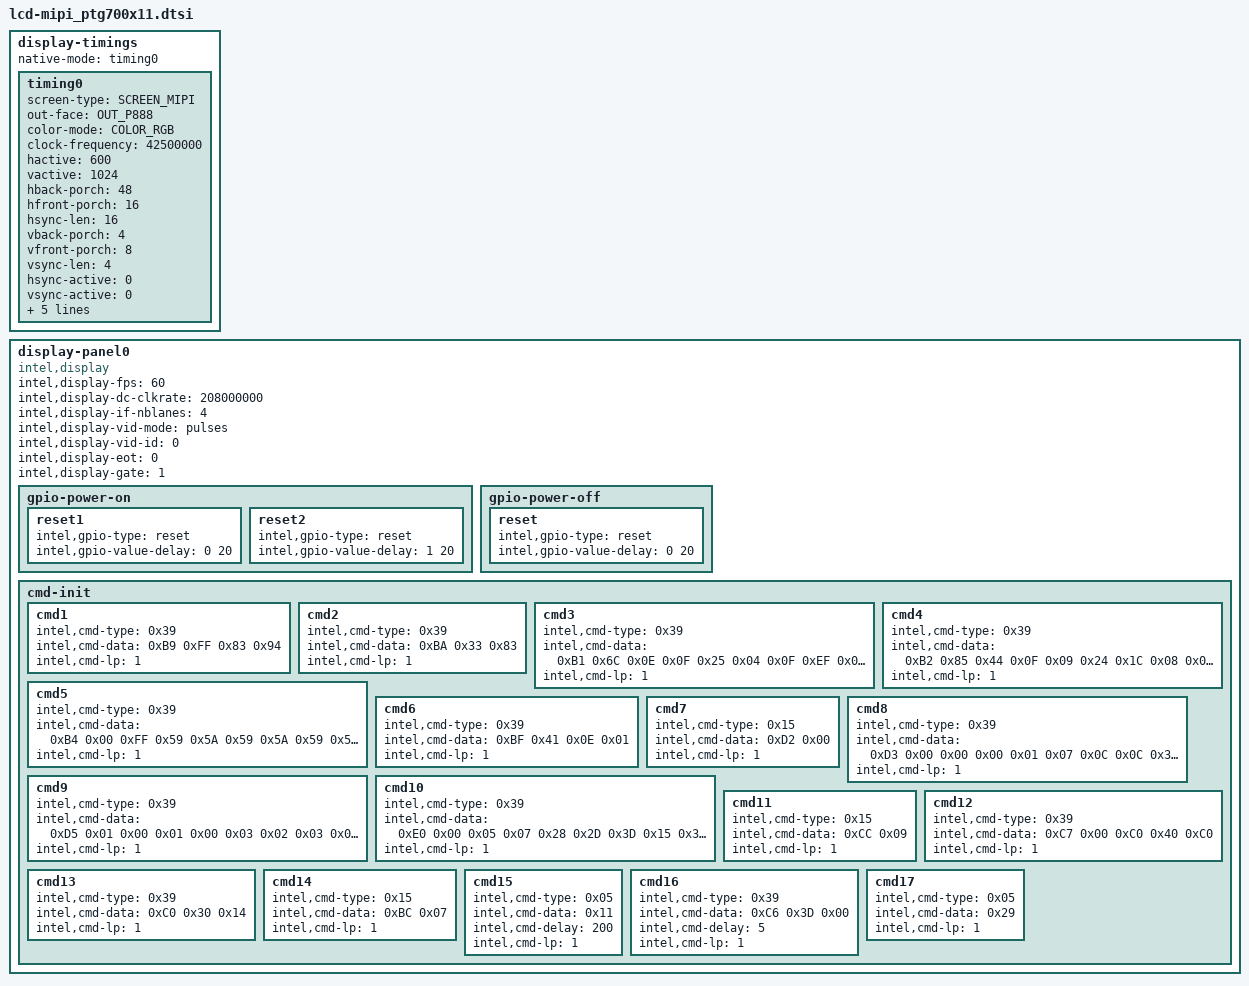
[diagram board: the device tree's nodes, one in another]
/*
 * sofia. lcd-mipi_ptg700x11.dtsi
 * this file include the definition about screen timing and init msg
 * macro definition at "include/dt-bindings/sofiafb/sofia_fb.h"
 */

	display-timings {
		native-mode = <&timing0>;
		timing0: timing0 {
			screen-type = <SCREEN_MIPI>;
			out-face    = <OUT_P888>;
			color-mode = <COLOR_RGB>;
			clock-frequency = <42500000>;
			hactive = <600>;
			vactive = <1024>;
			hback-porch = <48>;
			hfront-porch = <16>;
			hsync-len = <16>;
			vback-porch = <4>;
			vfront-porch = <8>;
			vsync-len = <4>;
			hsync-active = <0>;
			vsync-active = <0>;
			de-active = <0>;
			pixelclk-active = <0>;
			swap-rb = <0>;
			swap-rg = <0>;
			swap-gb = <0>;
		};
	};

	display-panel0 {
		compatible = "intel,display";

		/* intel,display-ramless = <1>; */
		intel,display-fps = <60>;
		intel,display-dc-clkrate = <208000000>;
		intel,display-if-nblanes = <4>;
		intel,display-vid-mode = "pulses";
		intel,display-vid-id = <0>;
		intel,display-eot = <0>;
		intel,display-gate = <1>;

		gpio-power-on {
			reset1 {
				intel,gpio-type = "reset";
				intel,gpio-value-delay = <0 20>;
			};
			reset2 {
				intel,gpio-type = "reset";
				intel,gpio-value-delay = <1 20>;
			};
		};

		gpio-power-off {
			reset {
				intel,gpio-type = "reset";
				intel,gpio-value-delay = <0 20>;
			};
		};

		cmd-init {
			cmd1 {
				intel,cmd-type = <0x39>;
				intel,cmd-data = <0xB9 0xFF 0x83 0x94>;
				intel,cmd-lp = <1>;
			};
			cmd2 {
				intel,cmd-type = <0x39>;
				intel,cmd-data = <0xBA 0x33 0x83>;
				intel,cmd-lp = <1>;
			};
			cmd3 {
				intel,cmd-type = <0x39>;
				intel,cmd-data = <0xB1
					0x6C 0x0E 0x0F 0x25 0x04 0x0F 0xEF 0x01
					0x67 0x9A 0x23 0x83 0xC0 0x8A 0x58>;
				intel,cmd-lp = <1>;
			};
			cmd4 {
				intel,cmd-type = <0x39>;
				intel,cmd-data = <0xB2
					0x85 0x44 0x0F 0x09 0x24 0x1C 0x08 0x08
					0x1C 0x4D 0x00 0x00>;
				intel,cmd-lp = <1>;
			};
			cmd5 {
				intel,cmd-type = <0x39>;
				intel,cmd-data = <0xB4
					0x00 0xFF 0x59 0x5A 0x59 0x5A 0x59 0x5A
					0x01 0x76 0x01 0x76>;
				intel,cmd-lp = <1>;
			};
			cmd6 {
				intel,cmd-type = <0x39>;
				intel,cmd-data = <0xBF 0x41 0x0E 0x01>;
				intel,cmd-lp = <1>;
			};
			cmd7 {
				intel,cmd-type = <0x15>;
				intel,cmd-data = <0xD2 0x00>;
				intel,cmd-lp = <1>;
			};
			cmd8 {
				intel,cmd-type = <0x39>;
				intel,cmd-data = <0xD3
					0x00 0x00 0x00 0x01 0x07 0x0C 0x0C 0x32
					0x10 0x07 0x00 0x05 0x00 0x20 0x0A 0x05
					0x09 0x00 0x32 0x10 0x08 0x00 0x21 0x21
					0x08 0x07 0x23 0x0D 0x07 0x47>;
				intel,cmd-lp = <1>;
			};
			cmd9 {
				intel,cmd-type = <0x39>;
				intel,cmd-data = <0xD5
					0x01 0x00 0x01 0x00 0x03 0x02 0x03 0x02
					0x21 0x20 0x21 0x20 0x18 0x02 0x18 0x02
					0x18 0x18 0x18 0x18 0x26 0x27 0x18 0x18
					0x18 0x18 0x18 0x18 0x18 0x18 0x18 0x18
					0x18 0x18 0x18 0x18 0x18 0x18 0x20 0x21
					0x18 0x18 0x18 0x18>;
				intel,cmd-lp = <1>;
			};
			cmd10 {
				intel,cmd-type = <0x39>;
				intel,cmd-data = <0xE0
					0x00 0x05 0x07 0x28 0x2D 0x3D 0x15 0x33
					0x05 0x09 0x0B 0x17 0x0F 0x13 0x15 0x12
					0x15 0x07 0x11 0x12 0x18 0x00 0x05 0x08
					0x28 0x2C 0x3D 0x15 0x33 0x05 0x09 0x0A
					0x16 0x0F 0x12 0x15 0x13 0x14 0x07 0x11
					0x11 0x17>;
				intel,cmd-lp = <1>;
			};
			cmd11 {
				intel,cmd-type = <0x15>;
				intel,cmd-data = <0xCC 0x09>;
				intel,cmd-lp = <1>;
			};
			cmd12 {
				intel,cmd-type = <0x39>;
				intel,cmd-data = <0xC7 0x00 0xC0 0x40 0xC0>;
				intel,cmd-lp = <1>;
			};
			cmd13 {
				intel,cmd-type = <0x39>;
				intel,cmd-data = <0xC0 0x30 0x14>;
				intel,cmd-lp = <1>;
			};
			cmd14 {
				intel,cmd-type = <0x15>;
				intel,cmd-data = <0xBC 0x07>;
				intel,cmd-lp = <1>;
			};
			cmd15 {
				intel,cmd-type = <0x05>;
				intel,cmd-data = <0x11>;
				intel,cmd-delay = <200>;
				intel,cmd-lp = <1>;
			};
			cmd16 {
				intel,cmd-type = <0x39>;
				intel,cmd-data = <0xC6 0x3D 0x00>;
				intel,cmd-delay = <5>;
				intel,cmd-lp = <1>;
			};
			cmd17 {
				intel,cmd-type = <0x05>;
				intel,cmd-data = <0x29>;
				intel,cmd-lp = <1>;
			};
		};
	};
